# TC35678 register map
Vendor: Toshiba Electronic Devices and Storage Corporation; File version: 0.1
CPU: CM0 r0p0, little endian, no MPU, no FPU, 4 interrupt priority bits
Registers are 32-bit, read-write, no defined reset value unless marked. A register's access mark holds for its fields unless they carry their own. Offsets are from the block's base; [hi:lo] are bit positions; {n}, {i} and the like mark numbered series; 'fields as' and 'values as' point back to an identical list.

## GPIO — General Purpose Input/Output
Base 0x4004E000
{0x0+4i} GPIOMON{i} ro (i=0..31) — GPIO{i} input monitor
  [0] GPIOMon — GPIO input monitor data Monitors the input of GPIO 1: High input 0: Low input Not dependent on the GppOutEn or hte GppMuxCfg.
0x80 GPIOA_MON ro — GPIOA input monitor
  fields as GPIOMON0
0x84 GPIOB_MON ro — GPIOB input monitor
  fields as GPIOMON0
{0x100+4i} GPIO_OUT{i} (i=0..31) — GPIO{i} output data
  [0] GPIOOut — GPIO output data Set the output level of the GPIOX. 1: High output 0: Low output The value is output only when GPIOOutEnX = 1 and GPIOMuxCfgX = 0.
0x180 GPIO_OUT3A — GPIOA output data
  fields as GPIO_OUT0
0x184 GPIO_OUTB — GPIOB output data
  fields as GPIO_OUT0
{0x200+4i} GPIO_OUT_EN{i} (i=0..31) — GPIO{i} output enable
  [0] GPIOOutEn — GPIO output enable. Enables GPIO output. 1: output enable 0: output disable
0x280 GPIOA_OUT_EN — GPIOA output enable
  fields as GPIO_OUT_EN0
0x284 GPIOB_OUT_EN0 — GPIOB output enable
  fields as GPIO_OUT_EN0
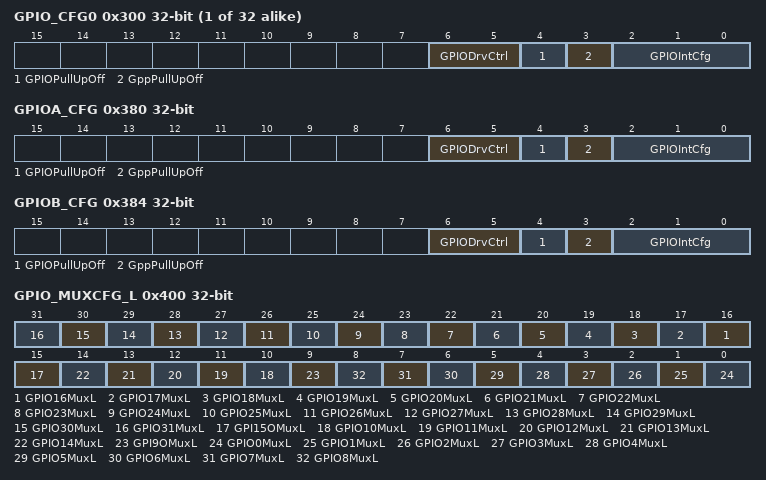
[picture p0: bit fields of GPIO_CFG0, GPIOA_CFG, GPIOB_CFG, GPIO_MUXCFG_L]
{0x300+4i} GPIO_CFG{i} (i=0..31) — GPIO{i} config
  [6:5] GPIODrvCtrl — GPIO0 drive control. To set GPIO drive settings. 00: 1 mA 01: 1.5 mA (default) 10: 2 mA 11: 4 mA Valid when the GPIO is set as output regardless of GPIOMuxCfg.
  [4] GPIOPullUpOff — GIO pull-up resister off Turn on/off the internal pull up resiter. 1: Internal pull-up off 0: Internal pull-up on GPIO0/3/4/9/10/14/15/20/21 are set as pull-up off. Others are set as pull-up on. When both GPIOPullDownOff = 0 and GPIOPullUpOff = 0 are to be set, the chip forces GPIOPullDownOff = 1 and GPIOPullUpOff = 0. Valid when the GPIO is set as input regardless of the GppMuxCfg.
  [3] GppPullUpOff — GIO pull-down resister off Turn on/off the internal pull down resiter. 1: Internal pull-down off 0: Internal pull-down on GPIO0/3/4/9/10/14/15/20/21 are set as pull-up off. Others are set as pull-up on. When both GPIOPullDownOff = 0 and GPIOPullUpOff = 0 are to be set, the chip forces GPIOPullDownOff = 1 and GPIOPullUpOff = 0. Valid when the GPIO is set as input regardless of the GppMuxCfg.
  [2:0] GPIOIntCfg — GPIO interrupt configuration (initial 00, R/W) Sets the polarity to use the GPIO as an external interrupt. 000: prohibit the interrupt. 001: detect rising edge 010: detect falling edge 011: detect both edges 100: detect high level 101: detect low level
0x380 GPIOA_CFG — GPIOA config
  fields as GPIO_CFG0
0x384 GPIOB_CFG — GPIOB config
  fields as GPIO_CFG0
0x400 GPIO_MUXCFG_L — GPIO multiplexer config L
  [n] GPIO{n}MuxL (n=16..31) — Bit 0 of GPIO multiplexer configuration.
  [15] GPI15OMuxL — Bit 0 of GPIO multiplexer configuration.
  [n] GPIO{n}MuxL (n=10..14) — Bit 0 of GPIO multiplexer configuration.
  [9] GPI9OMuxL — Bit 0 of GPIO multiplexer configuration.
  [n] GPIO{n}MuxL (n=0..8) — Bit 0 of GPIO multiplexer configuration.
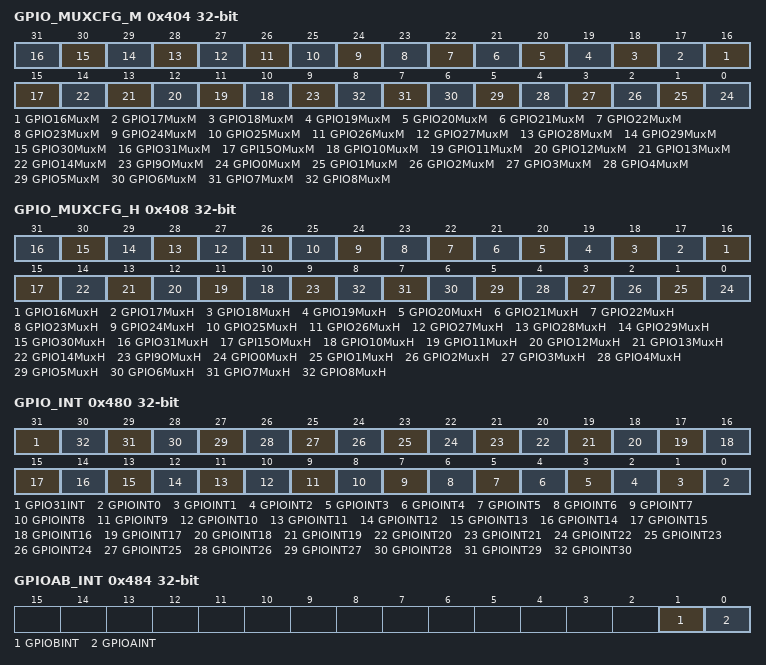
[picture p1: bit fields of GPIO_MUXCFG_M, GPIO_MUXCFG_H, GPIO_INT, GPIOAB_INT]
0x404 GPIO_MUXCFG_M — GPIO multiplexer config M
  [n] GPIO{n}MuxM (n=16..31) — Bit 1 of GPIO multiplexer configuration.
  [15] GPI15OMuxM — Bit 1 of GPIO multiplexer configuration.
  [n] GPIO{n}MuxM (n=10..14) — Bit 1 of GPIO multiplexer configuration.
  [9] GPI9OMuxM — Bit 1 of GPIO multiplexer configuration.
  [n] GPIO{n}MuxM (n=0..8) — Bit 1 of GPIO multiplexer configuration.
0x408 GPIO_MUXCFG_H — GPIO multiplexer config H
  [n] GPIO{n}MuxH (n=16..31) — Bit 2 of GPIO multiplexer configuration.
  [15] GPI15OMuxH — Bit 2 of GPIO multiplexer configuration.
  [n] GPIO{n}MuxH (n=10..14) — Bit 2 of GPIO multiplexer configuration.
  [9] GPI9OMuxH — Bit 2 of GPIO multiplexer configuration.
  [n] GPIO{n}MuxH (n=0..8) — Bit 2 of GPIO multiplexer configuration.
0x40C GPIOAB_MUXCFG — GPIOAB multiplexer config
  [0] GPIOABMuxCfg — 1: SWD, 0: GPIO
0x480 GPIO_INT ro — GPIO interrupt read
  [31] GPIO31INT — Read interrupt on the GPIO. 1: Interrupted 0: Not interrupted
  [n] GPIOINT{n} (n=0..30) — Read interrupt on the GPIO. 1: Interrupted 0: Not interrupted
0x484 GPIOAB_INT — GPIO interrupt read
  [1] GPIOBINT — Read interrupt on GPIOB. 1: Interrupted 0: Not interrupted
  [0] GPIOAINT — Read interrupt on GPIOA. 1: Interrupted 0: Not interrupted
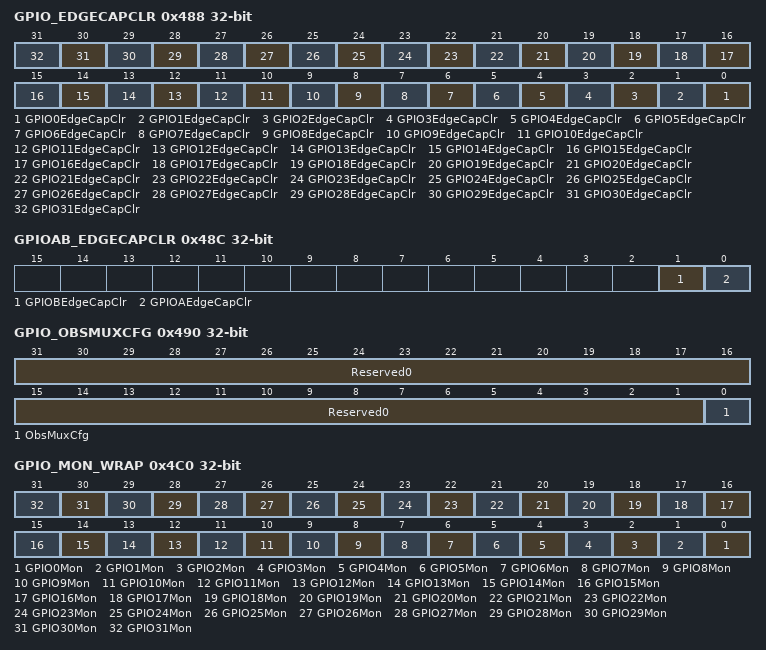
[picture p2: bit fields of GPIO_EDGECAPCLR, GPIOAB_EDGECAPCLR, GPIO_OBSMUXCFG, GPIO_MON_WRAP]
0x488 GPIO_EDGECAPCLR — GPIO edge interrupt capture clear
  [n] GPIO{n}EdgeCapClr (n=0..31) — Clear edge interrput capture on the GPIO. 1: Clear 0: Not clear
0x48C GPIOAB_EDGECAPCLR — GPIO edge interrupt capture clear
  [1] GPIOBEdgeCapClr — Clear edge interrput capture on GPIOB. 1: Clear 0: Not clear
  [0] GPIOAEdgeCapClr — Clear edge interrput capture on GPIOA. 1: Clear 0: Not clear
0x490 GPIO_OBSMUXCFG — GPIO Observation function selection register
  [31:1] Reserved0 — Always set 0.
  [0] ObsMuxCfg — Always set 3.
0x4C0 GPIO_MON_WRAP ro — GPIO Input Monitor Wrap Register
  [n] GPIO{n}Mon (n=0..31) — GPIO{n} input monitor data Monitors the input of GPIO{n} 1: High input 0: Low input
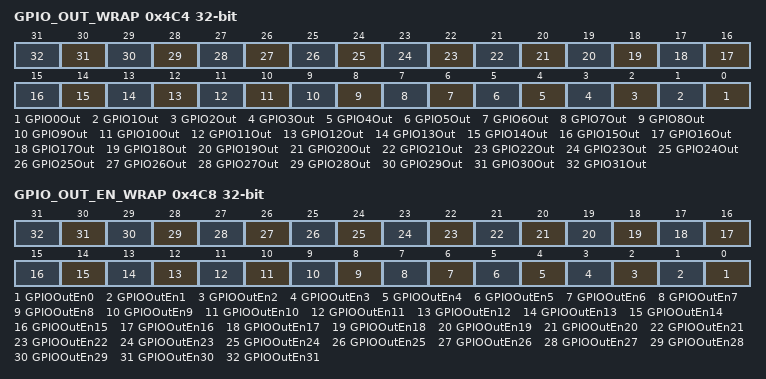
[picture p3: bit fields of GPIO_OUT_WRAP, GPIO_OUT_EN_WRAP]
0x4C4 GPIO_OUT_WRAP — GPIO Output data Wrap Register
  [n] GPIO{n}Out (n=0..31) — GPIO{n} output data Set the output level of GPIO{n} 1: High output 0: Low output
0x4C8 GPIO_OUT_EN_WRAP — GPIO Output Enable Wrap Register
  [n] GPIOOutEn{n} (n=0..31) — GPIO{n} output enable Enables GPIO{n} output 1: Output enable 0: Output disable
